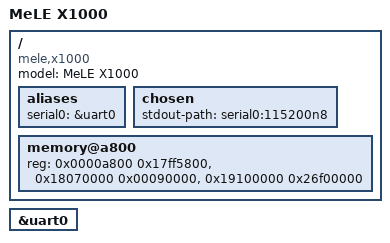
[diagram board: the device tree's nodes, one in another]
/dts-v1/;
#include "rtd1195.dtsi"
/ {
	compatible = "mele,x1000", "realtek,rtd1195";
	model = "MeLE X1000";
	aliases {
		serial0 = &uart0;
	};
	chosen {
		stdout-path = "serial0:115200n8";
	};
	memory@a800 {
		device_type = "memory";
		reg = <0x0000a800 0x17ff5800>,  
		      <0x18070000 0x00090000>,  
		      <0x19100000 0x26f00000>;  
	};
};
&uart0 {
	status = "okay";
};
